AUTOSAR XML (schema 00048)
package /SecurityArchitecture/ComponentTypes
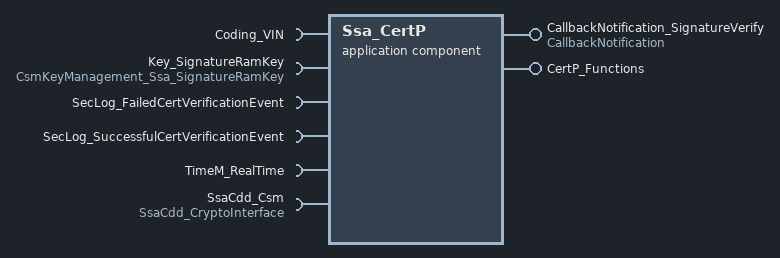
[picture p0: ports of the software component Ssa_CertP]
  application sw component type Ssa_CertP
    provide port CallbackNotification_SignatureVerify: server-com-spec{operation=CallbackNotification, queue-length=1}, provided-interface=CallbackNotification  # Callback notification from the CSM signature verification job used for verifying the signature of certificates. Configuration Variant(s): Asynchronous job processing.
    provide port CertP_Functions: provided-interface=CertP_Functions
      provided-com-specs:
        operation=AttributeCertificate_Parse, queue-length=1
        operation=Certificate_Compare, queue-length=1
        operation=Certificate_Parse, queue-length=1
        operation=Certificate_Verify, queue-length=1
        operation=Certificate_Verify_Extended, queue-length=1
        operation=ParseTime, queue-length=1
    6 x require port:
      Coding_VIN: client-com-spec=Get, required-interface=Coding_VIN
      Key_SignatureRamKey: required-com-specs=[KeyElementGet, KeyElementSet, KeySetValid], required-interface=CsmKeyManagement_Ssa_SignatureRamKey  # Sets a key just before the verification of a signature. Connect to a Csm Key which is able to store a signature key and is used in job of port CsmSignatureVerify.
      SecLog_FailedCertVerificationEvent: client-com-spec=FailedCertificateVerification, required-interface=SecLog_FailedCertVerificationEvent
      SecLog_SuccessfulCertVerificationEvent: client-com-spec=SuccessfulCertificateVerification, required-interface=SecLog_SuccessfulCertVerificationEvent
      TimeM_RealTime: required-com-specs=[Compare, Get, Set], required-interface=TimeM_RealTime
      SsaCdd_Csm: required-com-specs=[CancelJob, Hash, SignatureGenerate, SignatureVerify], required-interface=SsaCdd_CryptoInterface
    behavior Ssa_CertP_InternalBehavior: included-data-type-set=data-type=Ssa_KeyElementType
      6 x operation invoked event:
        OIT_CertP_Functions_AttributeCertificate_Parse_CertP_Functions_AttributeCertificate_Parse: start-on-event=Ssa_CertP_AttributeCertificate_Parse, operation=CertP_Functions.AttributeCertificate_Parse
        OIT_CertP_Certificate_Compare_CertP_Functions_Certificate_Compare: start-on-event=Ssa_CertP_Certificate_Compare, operation=CertP_Functions.Certificate_Compare
        OIT_CertP_Parse_CertP_Functions_CertP_Parse: start-on-event=Ssa_CertP_Certificate_Parse, operation=CertP_Functions.Certificate_Parse
        OIT_CertP_Verify_CertP_Functions_Cert_Verify: start-on-event=Ssa_CertP_Certificate_Verify, operation=CertP_Functions.Certificate_Verify
        OIT_CertP_Functions_Certificate_Verify_Extended_CertP_Functions_Certificate_Verify_Extended: start-on-event=Ssa_CertP_Certificate_Verify_Extended, operation=CertP_Functions.Certificate_Verify_Extended
        OIT_CallbackNotification_SignatureVerify_CallbackNotification_CallbackNotification_SignatureVerify_CallbackNotification: start-on-event=Ssa_CertP_CsmCallbackNotification_SignatureVerify, operation=CallbackNotification_SignatureVerify.CallbackNotification
      init event Ssa_CertP_InitEvent: start-on-event=Ssa_CertP_Init
      operation invoked event OIT_CertP_Functions_ParseTime_CertP_Functions_ParseTime: start-on-event=Ssa_CertP_ParseTime, operation=CertP_Functions.ParseTime
      port-api-options:
        enable-take-address=false, error-handling=NO-TRANSFORMER-ERROR-HANDLING, indirect-api=false, port=CallbackNotification_SignatureVerify
        enable-take-address=false, error-handling=NO-TRANSFORMER-ERROR-HANDLING, indirect-api=false, port=CertP_Functions
        enable-take-address=false, error-handling=NO-TRANSFORMER-ERROR-HANDLING, indirect-api=false, port=Coding_VIN
        enable-take-address=false, error-handling=NO-TRANSFORMER-ERROR-HANDLING, indirect-api=false, port=Key_SignatureRamKey
        enable-take-address=false, error-handling=NO-TRANSFORMER-ERROR-HANDLING, indirect-api=false, port=SecLog_FailedCertVerificationEvent
        enable-take-address=false, error-handling=NO-TRANSFORMER-ERROR-HANDLING, indirect-api=false, port=TimeM_RealTime
      8 x runnable:
        Ssa_CertP_AttributeCertificate_Parse: can-be-invoked-concurrently=true
        Ssa_CertP_Certificate_Compare: can-be-invoked-concurrently=true
        Ssa_CertP_Certificate_Parse: can-be-invoked-concurrently=true
        Ssa_CertP_Certificate_Verify  # Verifies the certificate against issuer.
          8 x sync call:
            SC_Coding_VIN_Get: operation=Coding_VIN.Get
            SC_Key_SignatureRamKey_KeyElementSet: operation=Key_SignatureRamKey.KeyElementSet
            SC_Key_SignatureRamKey_KeySetValid: operation=Key_SignatureRamKey.KeySetValid
            SC_SecLog_FailedCertVerificationEvent_FailedCertificateVerification: operation=SecLog_FailedCertVerificationEvent.FailedCertificateVerification
            SC_SecLog_SuccessfulCertVerificationEvent_SuccessfulCertificateVerification: operation=SecLog_SuccessfulCertVerificationEvent.SuccessfulCertificateVerification
            SC_TimeM_RealTime_TimeM_CompareRealTime: operation=TimeM_RealTime.Compare
            SC_TimeM_RealTime_TimeM_GetRealTime: operation=TimeM_RealTime.Get
            SC_SsaCdd_Csm_SignatureVerify: operation=SsaCdd_Csm.SignatureVerify
        Ssa_CertP_Certificate_Verify_Extended  # Verifies the certificate against issuer. Do additional checks, e.g. against ECU certificate.
          8 x sync call:
            SC_Coding_VIN_Get: operation=Coding_VIN.Get
            SC_Key_SignatureRamKey_KeyElementSet: operation=Key_SignatureRamKey.KeyElementSet
            SC_Key_SignatureRamKey_KeySetValid: operation=Key_SignatureRamKey.KeySetValid
            SC_SecLog_FailedCertVerificationEvent_FailedCertificateVerification: operation=SecLog_FailedCertVerificationEvent.FailedCertificateVerification
            SC_SecLog_SuccessfulCertVerificationEvent_SuccessfulCertificateVerification: operation=SecLog_SuccessfulCertVerificationEvent.SuccessfulCertificateVerification
            SC_TimeM_RealTime_Compare: operation=TimeM_RealTime.Compare
            SC_TimeM_RealTime_Get: operation=TimeM_RealTime.Get
            SC_SsaCdd_Csm_SignatureVerify: operation=SsaCdd_Csm.SignatureVerify
        Ssa_CertP_CsmCallbackNotification_SignatureVerify  # Configuration Variant(s): Asynchronous job processing.
        Ssa_CertP_Init
        Ssa_CertP_ParseTime: can-be-invoked-concurrently=true
  swc implementation Ssa_CertP_Implementation: behavior=Ssa_CertP_InternalBehavior
    code-descriptors:
      code Default: artifact-descriptors=autosar-engineering-object=category=SWSRC
